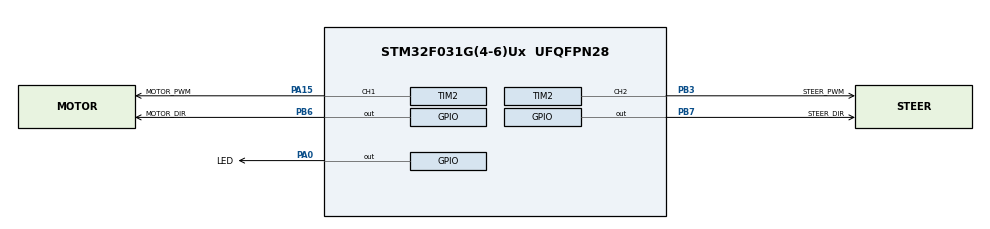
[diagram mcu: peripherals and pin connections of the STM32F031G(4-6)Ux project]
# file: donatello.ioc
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Mcu.Family=STM32F0
Mcu.Name=STM32F031G(4-6)Ux
Mcu.Package=UFQFPN28
PA0.GPIO_Label=LED
PA0.GPIO_PuPd=GPIO_NOPULL
PA0.Signal=GPIO_Output
PA13.GPIO_Label=SWDIO
PA13.Mode=Serial_Wire
PA13.Signal=SYS_SWDIO
PA14.GPIO_Label=SWCLK
PA14.Mode=Serial_Wire
PA14.Signal=SYS_SWCLK
PA15.GPIO_Label=MOTOR_PWM
PA15.Signal=S_TIM2_CH1_ETR
PB3.GPIO_Label=STEER_PWM
PB3.Signal=S_TIM2_CH2
PB6.GPIO_Label=MOTOR_DIR
PB6.Signal=GPIO_Output
PB7.GPIO_Label=STEER_DIR
PB7.Signal=GPIO_Output
ProjectManager.HeapSize=0x200
ProjectManager.StackSize=0x400
ProjectManager.TargetToolchain=STM32CubeIDE
SH.S_TIM2_CH1_ETR.0=TIM2_CH1,PWM Generation1 CH1
SH.S_TIM2_CH2.0=TIM2_CH2,PWM Generation2 CH2
TIM2.Channel-PWM\ Generation1\ CH1=TIM_CHANNEL_1
TIM2.Channel-PWM\ Generation2\ CH2=TIM_CHANNEL_2
TIM2.Period=1000
board=custom

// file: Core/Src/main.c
/* USER CODE BEGIN Header */
/**
  ******************************************************************************
  * @file           : main.c
  * @brief          : Main program body
  ******************************************************************************
  * @attention
  *
  * <h2><center>&copy; Copyright (c) 2020 STMicroelectronics.
  * All rights reserved.</center></h2>
  *
  * This software component is licensed by ST under BSD 3-Clause license,
  * the "License"; You may not use this file except in compliance with the
  * License. You may obtain a copy of the License at:
  *                        opensource.org/licenses/BSD-3-Clause
  *
  ******************************************************************************
  */
/* USER CODE END Header */

#include "main.h"

TIM_HandleTypeDef htim2;

void SystemClock_Config(void);
static void MX_GPIO_Init(void);
static void MX_TIM2_Init(void);

int main(void)
{

  /* MCU Configuration--------------------------------------------------------*/

  /* Reset of all peripherals, Initializes the Flash interface and the Systick. */
  HAL_Init();

  /* Configure the system clock */
  SystemClock_Config();

  /* Initialize all configured peripherals */
  MX_GPIO_Init();
  MX_TIM2_Init();
  /* USER CODE BEGIN 2 */

  //HAL_GPIO_WritePin(MOTOR_DIR_GPIO_Port, MOTOR_DIR_Pin, GPIO_PIN_SET);
  //HAL_TIM_PWM_Start(&htim2, TIM_CHANNEL_1);

  //HAL_GPIO_WritePin(STEER_DIR_GPIO_Port,  STEER_DIR_Pin, GPIO_PIN_SET);
  //HAL_TIM_PWM_Start(&htim2, TIM_CHANNEL_2);

  /* USER CODE END 2 */

  /* Infinite loop */
  while (1)
  {

    /* USER CODE BEGIN 3 */

		HAL_GPIO_TogglePin(LED_GPIO_Port, LED_Pin);
		HAL_Delay(1000);

/*
		TIM2->CCR1 = 200;
		HAL_GPIO_WritePin(MOTOR_DIR_GPIO_Port, MOTOR_DIR_Pin, GPIO_PIN_SET);
		HAL_GPIO_TogglePin(LED_GPIO_Port, LED_Pin);
		HAL_Delay(1000);

		TIM2->CCR1 = 200;
		HAL_GPIO_WritePin(MOTOR_DIR_GPIO_Port, MOTOR_DIR_Pin, GPIO_PIN_RESET);
		HAL_GPIO_TogglePin(LED_GPIO_Port, LED_Pin);
		HAL_Delay(1000);

		TIM2->CCR1 = 0;
		HAL_GPIO_TogglePin(LED_GPIO_Port, LED_Pin);
		HAL_Delay(1000);
*/
  }
  /* USER CODE END 3 */
}

void SystemClock_Config(void)
{
  RCC_OscInitTypeDef RCC_OscInitStruct = {0};
  RCC_ClkInitTypeDef RCC_ClkInitStruct = {0};

  /** Initializes the CPU, AHB and APB busses clocks
  */
  RCC_OscInitStruct.OscillatorType = RCC_OSCILLATORTYPE_HSI;
  RCC_OscInitStruct.HSIState = RCC_HSI_ON;
  RCC_OscInitStruct.HSICalibrationValue = RCC_HSICALIBRATION_DEFAULT;
  RCC_OscInitStruct.PLL.PLLState = RCC_PLL_NONE;
  if (HAL_RCC_OscConfig(&RCC_OscInitStruct) != HAL_OK)
  {
    Error_Handler();
  }
  /** Initializes the CPU, AHB and APB busses clocks
  */
  RCC_ClkInitStruct.ClockType = RCC_CLOCKTYPE_HCLK|RCC_CLOCKTYPE_SYSCLK
                              |RCC_CLOCKTYPE_PCLK1;
  RCC_ClkInitStruct.SYSCLKSource = RCC_SYSCLKSOURCE_HSI;
  RCC_ClkInitStruct.AHBCLKDivider = RCC_SYSCLK_DIV1;
  RCC_ClkInitStruct.APB1CLKDivider = RCC_HCLK_DIV1;

  if (HAL_RCC_ClockConfig(&RCC_ClkInitStruct, FLASH_LATENCY_0) != HAL_OK)
  {
    Error_Handler();
  }
}

static void MX_TIM2_Init(void)
{

  TIM_MasterConfigTypeDef sMasterConfig = {0};
  TIM_OC_InitTypeDef sConfigOC = {0};

  htim2.Instance = TIM2;
  htim2.Init.Prescaler = 0;
  htim2.Init.CounterMode = TIM_COUNTERMODE_UP;
  htim2.Init.Period = 1000;
  htim2.Init.ClockDivision = TIM_CLOCKDIVISION_DIV1;
  htim2.Init.AutoReloadPreload = TIM_AUTORELOAD_PRELOAD_DISABLE;
  if (HAL_TIM_PWM_Init(&htim2) != HAL_OK)
  {
    Error_Handler();
  }
  sMasterConfig.MasterOutputTrigger = TIM_TRGO_RESET;
  sMasterConfig.MasterSlaveMode = TIM_MASTERSLAVEMODE_DISABLE;
  if (HAL_TIMEx_MasterConfigSynchronization(&htim2, &sMasterConfig) != HAL_OK)
  {
    Error_Handler();
  }
  sConfigOC.OCMode = TIM_OCMODE_PWM1;
  sConfigOC.Pulse = 0;
  sConfigOC.OCPolarity = TIM_OCPOLARITY_HIGH;
  sConfigOC.OCFastMode = TIM_OCFAST_DISABLE;
  if (HAL_TIM_PWM_ConfigChannel(&htim2, &sConfigOC, TIM_CHANNEL_1) != HAL_OK)
  {
    Error_Handler();
  }
  if (HAL_TIM_PWM_ConfigChannel(&htim2, &sConfigOC, TIM_CHANNEL_2) != HAL_OK)
  {
    Error_Handler();
  }
  HAL_TIM_MspPostInit(&htim2);

}

static void MX_GPIO_Init(void)
{
  GPIO_InitTypeDef GPIO_InitStruct = {0};

  /* GPIO Ports Clock Enable */
  __HAL_RCC_GPIOA_CLK_ENABLE();
  __HAL_RCC_GPIOB_CLK_ENABLE();

  /*Configure GPIO pin Output Level */
  HAL_GPIO_WritePin(LED_GPIO_Port, LED_Pin, GPIO_PIN_RESET);

  /*Configure GPIO pin Output Level */
  HAL_GPIO_WritePin(GPIOB, MOTOR_DIR_Pin|STEER_DIR_Pin, GPIO_PIN_RESET);

  /*Configure GPIO pin : LED_Pin */
  GPIO_InitStruct.Pin = LED_Pin;
  GPIO_InitStruct.Mode = GPIO_MODE_OUTPUT_PP;
  GPIO_InitStruct.Pull = GPIO_NOPULL;
  GPIO_InitStruct.Speed = GPIO_SPEED_FREQ_LOW;
  HAL_GPIO_Init(LED_GPIO_Port, &GPIO_InitStruct);

  /*Configure GPIO pins : MOTOR_DIR_Pin STEER_DIR_Pin */
  GPIO_InitStruct.Pin = MOTOR_DIR_Pin|STEER_DIR_Pin;
  GPIO_InitStruct.Mode = GPIO_MODE_OUTPUT_PP;
  GPIO_InitStruct.Pull = GPIO_NOPULL;
  GPIO_InitStruct.Speed = GPIO_SPEED_FREQ_LOW;
  HAL_GPIO_Init(GPIOB, &GPIO_InitStruct);

}

void Error_Handler(void)
{
}

/************************ (C) COPYRIGHT STMicroelectronics *****END OF FILE****/
